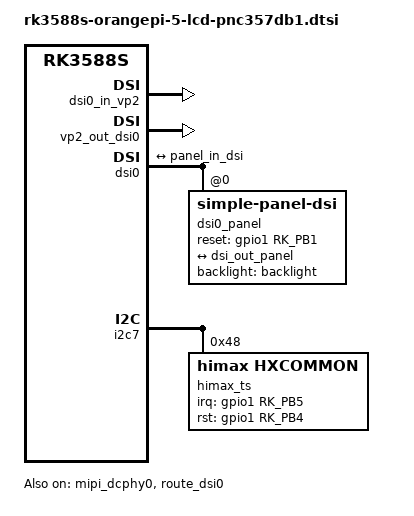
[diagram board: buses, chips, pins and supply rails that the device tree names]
// SPDX-License-Identifier: (GPL-2.0+ OR MIT)
/* MIPI display panel PNC357DB1-4
 * name: rk3588s-orangepi-5-lcd-pnc357db1.dtsi
 * mipi_dcphy0 needs to be enabled
 * when dsi0 is enabled
 */
// below are from rk3588s-tablet-12c.dtsi and rk3588s-tablet-rk806

&mipi_dcphy0 {
        status = "okay";
};

&mipi_dcphy1 {
		status = "disabled";
};

&route_dsi0 {
	status = "okay";
	connect = <&vp2_out_dsi0>;
};

&dsi0_in_vp2 {
	status = "okay";
};

&vp2_out_dsi0 {
	status = "okay";
};

&dsi0 {
	status = "okay";
	rockchip,lane-rate = <676000>;
	dsi0_panel: panel@0 {
		status = "okay";
		compatible = "simple-panel-dsi";
		reg = <0>;
		backlight = <&backlight>;

		// here I commented out the vdd-supply since there is no vcc_avee in opi5 dtsi
		// power-supply = <&vcc_avee>;
		// reset-gpios = <&gpio3 RK_PC6 GPIO_ACTIVE_HIGH>; GPIO3_C6_u
		// reset pin are modified to orange pi 5 reset gpio GPIO1_B1
		reset-gpios = <&gpio1 RK_PB1 GPIO_ACTIVE_HIGH>;
		reset-enable-combined;
		pinctrl-names = "default";
		// pinctrl-0 = <&lcd_rst_gpio>;
		// pinctrl are modified according to orange pi 5 dtsi
		pinctrl-0 = <&lcd0_rst_gpio>;
		// below are unchanged from rk3588s-tablet-12c.dtsi
		reset-delay-ms = <120>;
		enable-delay-ms = <120>;
		prepare-delay-ms = <120>;
		init-delay-ms = <120>;
		unprepare-delay-ms = <120>;
		disable-delay-ms = <120>;
		compressed-data;
		dsi,flags = <(MIPI_DSI_MODE_VIDEO | MIPI_DSI_MODE_VIDEO_BURST |
				MIPI_DSI_MODE_LPM | MIPI_DSI_MODE_EOT_PACKET)>;
		dsi,format = <MIPI_DSI_FMT_RGB888>;
		dsi,lanes = <4>;

		slice-width = <1600>;
		slice-height = <40>;
		version-major = <1>;
		version-minor = <1>;
		panel-init-sequence = [
			0a 31 58 11 00 00 89 30 80 0A 00 06 40 00 28 06 40 06 40 02 00 04 21 00 20 05 D0 00 16 00 0C 02 77 00 DA 18 00 10 E0 03 0C 20 00 06 0B 0B 33 0E 1C 2A 38 46 54 62 69 70 77 79 7B 7D 7E 01 02 01 00 09 40 09 BE 19 FC 19 FA 19 F8 1A 38 1A 78 1A B6 2A F6 2B 34 2B 74 3B 74 6B 74
			39 00 06 B9 83 12 1A 55 00
			39 00 03 51 08 00
			39 00 02 53 24
			39 00 1D B1 1C 6B 6B 27 E7 00 1B 12 20 20 2D 2D 1F 33 31 40 CD FF 1A 05 15 98 00 88 F9 FF FF CF
			39 00 12 B2 00 6A 40 00 00 14 6E 40 73 02 80 21 21 00 00 10 27
			39 00 2D B4 64 00 08 7F 08 7F 00 62 01 72 01 72 00 60 00 00 0A 08 00 29 05 05 05 00 00 00 00 00 00 00 00 00 00 00 FF 00 FF 14 00 00 0F 0F 2D 2D
			39 00 04 B6 8F 8F 03
			39 00 03 BC 06 02
			39 00 07 C0 34 34 44 00 08 D8
			39 00 06 C9 00 1E 80 A5 01
			39 00 07 CB 00 13 38 00 0B 27
			39 00 02 CC 02
			39 00 02 D1 07
			39 00 29 D3 00 C0 08 08 08 04 04 04 14 02 07 07 07 31 13 12 12 12 03 03 03 32 10 11 00 11 32 10 03 00 03 32 10 03 00 03 00 00 FF 00
			39 00 31 D5 19 19 18 18 02 02 03 03 04 04 05 05 06 06 07 07 00 00 01 01 18 18 40 40 20 20 18 18 18 18 40 40 18 18 2F 2F 31 31 2F 2F 31 31 18 18 41 41 41 41
			39 00 31 D6 40 40 18 18 05 05 04 04 03 03 02 02 01 01 00 00 07 07 06 06 18 18 19 19 20 20 18 18 18 18 40 40 18 18 2F 2F 31 31 2F 2F 31 31 18 18 41 41 41 41
			39 00 40 E1 11 00 00 89 30 80 0A 00 06 40 00 28 06 40 06 40 02 00 04 21 00 20 05 D0 00 16 00 0C 02 77 00 DA 18 00 10 E0 03 0C 20 00 06 0B 0B 33 0E 1C 2A 38 46 54 62 69 70 77 79 7B 7D 7E 01 02 01 00 09
			39 00 0C E7 06 14 14 1A 23 38 00 23 5D 02 02
			39 00 02 BD 01
			39 00 04 B1 01 23 00
			39 00 25 D8 20 00 02 22 00 00 20 00 02 22 00 00 20 00 02 22 00 00 20 00 02 22 00 00 20 00 02 22 00 00 20 00 02 22 00 00
			39 00 1A E1 40 09 BE 19 FC 19 FA 19 F8 1A 38 1A 78 1A B6 2A F6 2B 34 2B 74 3B 74 6B F4
			39 00 0D E7 02 00 40 01 84 13 BE 14 48 00 04 26
			39 00 08 CB 1F 55 03 28 0D 08 0A
			39 00 02 BD 02
			39 00 0D D8 AF FF FA FA BF EA AF FF FA FA BF EA
			39 00 23 E7 01 05 01 03 01 03 04 02 02 24 00 24 81 02 40 00 29 60 03 02 01 00 00 00 00 00 00 00 00 00 00 00 00 00
			39 00 02 BD 03
			39 00 19 D8 AA AA AA AB BF EA AA AA AA AB BF EA AF FF FA FA BF EA AF FF FA FA BF EA
			39 00 03 E1 01 3F
			39 00 02 BD 00
			39 00 2F E0 00 13 30 36 40 78 8B 94 95 97 94 94 91 8F 8F 8B 8A 8C 8E A6 B7 4D 7F 00 13 30 36 40 78 8B 94 95 97 94 94 91 8F 8F 8B 8A 8C 8E A6 B7 4D 7F
			39 00 05 BA 70 03 A8 92
			39 00 25 D8 EA AA AA AE AA AF EA AA AA AE AA AF E0 00 0A 2E 80 2F E0 00 0A 2E 80 2F E0 00 0A 2E 80 2F E0 00 0A 2E 80 2F
			39 00 02 BD 00
			39 00 02 C1 01
			39 00 02 BD 01
			39 00 3B C1 00 04 08 0C 10 14 18 1C 1F 23 27 2B 2F 33 37 3B 3F 43 47 4B 52 5A 62 69 71 79 81 89 91 98 A1 A9 B1 B9 C1 CA D2 DA E3 EA F4 F8 F9 FB FD FF 16 A4 44 16 90 E7 F9 71 A0 F3 1F 40
			39 00 02 BD 02
			39 00 3B C1 00 04 08 0C 10 14 18 1C 20 24 28 2D 31 35 39 3D 41 45 49 4D 55 5D 65 6D 75 7D 85 8D 94 9C A4 AC B4 BC C4 CC D4 DC E4 EC F4 F8 FA FC FE FF 06 AA FC 5B FF FF A4 F9 86 F9 55 40
			39 00 02 BD 03
			39 00 3B C1 00 04 07 0B 0F 13 17 1B 1F 23 27 2C 30 33 38 3C 40 44 48 4C 53 5B 63 6B 72 7A 82 89 91 99 A1 A9 B1 B9 C1 C9 D1 DA E2 EA F3 F6 F9 FA FE FF 0F 9A FC 31 40 E4 FB E9 A3 D9 77 00
			39 00 02 BD 02
			39 00 02 BF 72
			39 00 02 BD 00
			39 00 08 BF FD 00 80 9C 10 00 80
			39 00 02 E9 DE
			39 00 04 B1 CC 03 00
			39 00 02 E9 3F
			39 00 07 D0 07 C0 08 03 11 00
			39 00 03 B0 00 00
			39 00 02 E9 CF
			39 00 02 BA 03
			39 00 02 E9 3F
			39 00 01 11
			39 00 01 29
		];

		panel-exit-sequence = [

		];

		width-mm = <166>;
		height-mm = <266>;
		rotation = <90>;
		bpc = <8>;

			dsi0_timing0: panel-timing {
				clock-frequency = <275000000>;
				hactive = <1600>;
				vactive = <2560>;
				hfront-porch = <60>;
				hsync-len = <20>;
				hback-porch = <20>;
				vfront-porch = <112>;
				vsync-len = <4>;
				vback-porch = <18>;
				hsync-active = <0>;
				vsync-active = <0>;
				de-active = <0>;
				pixelclk-active = <0>;
			};

		ports {
			#address-cells = <1>;
			#size-cells = <0>;

			port@0 {
				reg = <0>;
				panel_in_dsi: endpoint {
					remote-endpoint = <&dsi_out_panel>;
				};
			};
		};
	};

	ports {
		#address-cells = <1>;
		#size-cells = <0>;

		port@1 {
			reg = <1>;
			dsi_out_panel: endpoint {
				remote-endpoint = <&panel_in_dsi>;
			};
		};
	};
};
&dsi1 {
	status = "disabled";
};

// modified from rk3588s-tablet-12c.dtsi
// change i2c4 in fyde tablet to i2c7 in orange pi 5
// this only makes touch screen work. For stylus, install fydetab postinst pkg
&i2c7 {
	status = "okay";
	pinctrl-names = "default";
	pinctrl-0 = <&i2c7m0_xfer>; // modified from i2c4m0_xfer

	himax_ts@48 {
        status = "okay";
        compatible = "himax,hxcommon";
        reg = <0x48>;
        interrupt-parent = <&gpio1>;
        interrupts = <RK_PB5 IRQ_TYPE_LEVEL_LOW>;
        himax,panel-coords = <0 1600 0 2560>;
        himax,display-coords = <0 1600 0 2560>;
        himax,irq-gpio = <&gpio1 RK_PB5 GPIO_ACTIVE_HIGH>;
        himax,rst-gpio = <&gpio1 RK_PB4 GPIO_ACTIVE_HIGH>;
        report_type = <1>;
        panel = <&dsi0_panel>;
	};
};


&dsi1 {
	status = "disabled";
};

// i2c2 for dsi1
// &i2c2 {
// 	status = "okay";

// 	gt9xx_0: touchscreen@14 {
// 		compatible = "goodix,gt9271";
// 		reg = <0x14>;
// 		interrupt-parent = <&gpio1>;
// 		interrupts = <RK_PA7 IRQ_TYPE_LEVEL_LOW>;
// 		irq-gpios = <&gpio1 RK_PA7 IRQ_TYPE_LEVEL_LOW>;
// 		reset-gpios = <&gpio1 RK_PA4 GPIO_ACTIVE_HIGH>;
// 		touchscreen-inverted-x;
// 		//touchscreen-inverted-y;
// 		touchscreen-swapped-x-y;
// 		touchscreen-size-x = <1280>;
// 		touchscreen-size-y = <800>;
// 		status = "okay";
// 	};
// };
